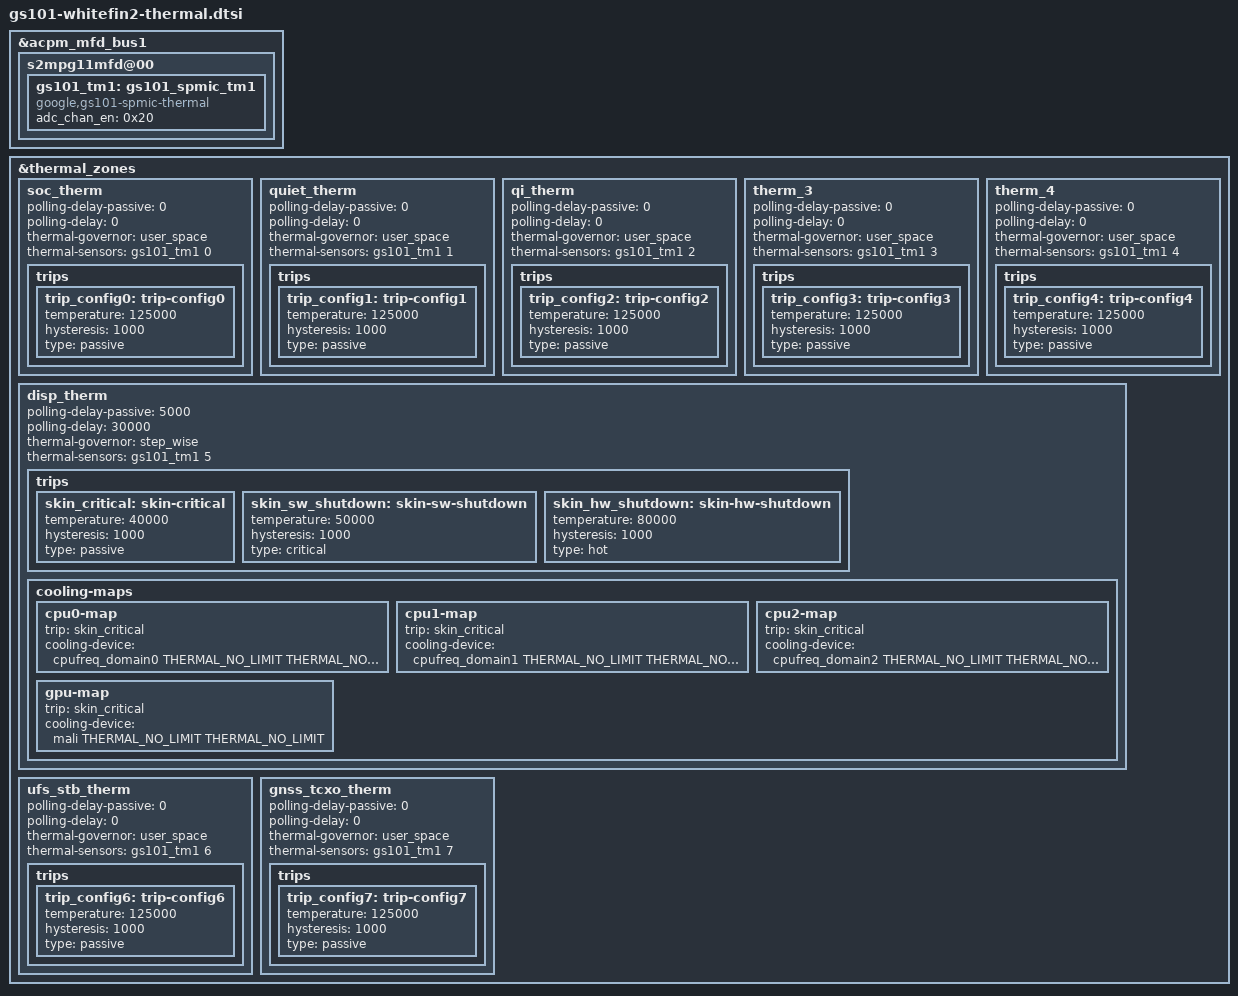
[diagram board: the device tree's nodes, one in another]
// SPDX-License-Identifier: GPL-2.0
/*
 * Google GS101 Whitefin2-specific thermal device tree source
 *
 * Copyright (c) 2020 Google, LLC
 *		https://www.google.com
 */

#include <dt-bindings/thermal/thermal.h>

&acpm_mfd_bus1 {
	s2mpg11mfd@00 {
		gs101_tm1: gs101_spmic_tm1 {
			compatible = "google,gs101-spmic-thermal";
			#thermal-sensor-cells = <1>;
			adc_chan_en = /bits/ 8 <0x20>;
		};
	};
};

/* Thermal Zones */
&thermal_zones {
	soc_therm {
		polling-delay-passive = <0>;
		polling-delay = <0>;
		thermal-governor = "user_space";
		thermal-sensors = <&gs101_tm1 0>;
		trips {
			trip_config0: trip-config0 {
				temperature = <125000>;
				hysteresis = <1000>;
				type = "passive";
			};
		};
	};
	quiet_therm {
		polling-delay-passive = <0>;
		polling-delay = <0>;
		thermal-governor = "user_space";
		thermal-sensors = <&gs101_tm1 1>;
		trips {
			trip_config1: trip-config1 {
				temperature = <125000>;
				hysteresis = <1000>;
				type = "passive";
			};
		};
	};
	qi_therm {
		polling-delay-passive = <0>;
		polling-delay = <0>;
		thermal-governor = "user_space";
		thermal-sensors = <&gs101_tm1 2>;
		trips {
			trip_config2: trip-config2 {
				temperature = <125000>;
				hysteresis = <1000>;
				type = "passive";
			};
		};
	};
	therm_3 {
		polling-delay-passive = <0>;
		polling-delay = <0>;
		thermal-governor = "user_space";
		thermal-sensors = <&gs101_tm1 3>;
		trips {
			trip_config3: trip-config3 {
				temperature = <125000>;
				hysteresis = <1000>;
				type = "passive";
			};
		};
	};
	therm_4 {
		polling-delay-passive = <0>;
		polling-delay = <0>;
		thermal-governor = "user_space";
		thermal-sensors = <&gs101_tm1 4>;
		trips {
			trip_config4: trip-config4 {
				temperature = <125000>;
				hysteresis = <1000>;
				type = "passive";
			};
		};
	};
	disp_therm {
		polling-delay-passive = <5000>;
		polling-delay = <30000>;
		thermal-governor = "step_wise";
		thermal-sensors = <&gs101_tm1 5>;
		trips {
			skin_critical: skin-critical {
				temperature = <40000>;
				hysteresis = <1000>;
				type = "passive";
			};
			skin_sw_shutdown: skin-sw-shutdown {
				temperature = <50000>;
				hysteresis = <1000>;
				type = "critical";
			};
			skin_hw_shutdown: skin-hw-shutdown {
				temperature = <80000>;
				hysteresis = <1000>;
				type = "hot";
			};
		};
		cooling-maps {
				cpu0-map {
					trip = <&skin_critical>;
					cooling-device = <&cpufreq_domain0
						THERMAL_NO_LIMIT
						THERMAL_NO_LIMIT>;
				};
				cpu1-map {
					trip = <&skin_critical>;
					cooling-device = <&cpufreq_domain1
						THERMAL_NO_LIMIT
						THERMAL_NO_LIMIT>;
				};
				cpu2-map {
					trip = <&skin_critical>;
					cooling-device = <&cpufreq_domain2
						THERMAL_NO_LIMIT
						THERMAL_NO_LIMIT>;
				};
				gpu-map {
					trip = <&skin_critical>;
					cooling-device = <&mali
						THERMAL_NO_LIMIT
						THERMAL_NO_LIMIT>;
				};
		};
	};
	ufs_stb_therm {
		polling-delay-passive = <0>;
		polling-delay = <0>;
		thermal-governor = "user_space";
		thermal-sensors = <&gs101_tm1 6>;
		trips {
			trip_config6: trip-config6 {
				temperature = <125000>;
				hysteresis = <1000>;
				type = "passive";
			};
		};
	};
	gnss_tcxo_therm {
		polling-delay-passive = <0>;
		polling-delay = <0>;
		thermal-governor = "user_space";
		thermal-sensors = <&gs101_tm1 7>;
		trips {
			trip_config7: trip-config7 {
				temperature = <125000>;
				hysteresis = <1000>;
				type = "passive";
			};
		};
	};
};
